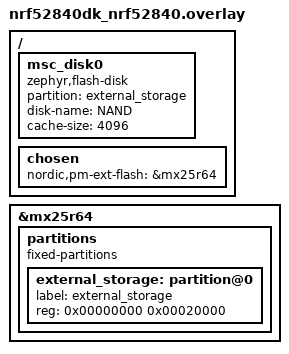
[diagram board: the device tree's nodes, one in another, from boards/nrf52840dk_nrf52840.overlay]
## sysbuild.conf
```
#
# Copyright (c) 2023 Nordic Semiconductor
#
# SPDX-License-Identifier: LicenseRef-Nordic-5-Clause
#

SB_CONFIG_BOOTLOADER_MCUBOOT=y
SB_CONFIG_DFU_ZIP=y
SB_CONFIG_DFU_ZIP_BLUETOOTH_MESH_METADATA=y
SB_CONFIG_DFU_ZIP_BLUETOOTH_MESH_FWID_CUSTOM=y
SB_CONFIG_DFU_ZIP_BLUETOOTH_MESH_FWID_CUSTOM_HEX="deadbeef"
```

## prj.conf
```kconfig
#
# Copyright (c) 2022 Nordic Semiconductor ASA
#
# SPDX-License-Identifier: LicenseRef-Nordic-5-Clause
#

# General configuration
CONFIG_SYSTEM_WORKQUEUE_STACK_SIZE=2048
CONFIG_NVS=y
CONFIG_SETTINGS=y
CONFIG_NVS_LOOKUP_CACHE=y
CONFIG_SETTINGS_NVS_NAME_CACHE=y
CONFIG_HWINFO=y
CONFIG_DK_LIBRARY=y
CONFIG_LOG=y
CONFIG_LTO=y
CONFIG_ISR_TABLES_LOCAL_DECLARATION=y

# Bootloader configuration
CONFIG_NCS_APPLICATION_BOOT_BANNER_STRING="Mesh DFU Distributor"
CONFIG_BOOTLOADER_MCUBOOT=y
CONFIG_NCS_SAMPLE_MCUMGR_BT_OTA_DFU=y
CONFIG_MCUBOOT_GENERATE_CONFIRMED_IMAGE=y
CONFIG_MCUBOOT_IMGTOOL_SIGN_VERSION="1.0.0+0"

# Bluetooth configuration
CONFIG_BT=y
CONFIG_BT_DEVICE_NAME="Mesh DFU Distributor"
CONFIG_BT_L2CAP_TX_BUF_COUNT=8
CONFIG_BT_OBSERVER=y
CONFIG_BT_PERIPHERAL=y
CONFIG_BT_SETTINGS=y
CONFIG_BT_ECC=y
CONFIG_BT_TINYCRYPT_ECC=y
CONFIG_BT_BUF_CMD_TX_COUNT=4

# Disable unused Bluetooth features
CONFIG_BT_CTLR_LE_ENC=n
CONFIG_BT_DATA_LEN_UPDATE=n
CONFIG_BT_PHY_UPDATE=n
CONFIG_BT_CTLR_CHAN_SEL_2=n
CONFIG_BT_CTLR_PRIVACY=n
CONFIG_BT_CTLR_PHY_2M=n

# Bluetooth Mesh configuration
CONFIG_BT_MESH=y
CONFIG_BT_MESH_RELAY=y
CONFIG_BT_MESH_FRIEND=y
CONFIG_BT_MESH_MSG_CACHE_SIZE=256
CONFIG_BT_MESH_ADV_BUF_COUNT=128
CONFIG_BT_MESH_TX_SEG_MAX=10
CONFIG_BT_MESH_RX_SEG_MAX=10
CONFIG_BT_MESH_TX_SEG_MSG_COUNT=2
CONFIG_BT_MESH_RX_SEG_MSG_COUNT=2
CONFIG_BT_MESH_PB_GATT=y
CONFIG_BT_MESH_PB_ADV=y
CONFIG_BT_MESH_GATT_PROXY=y
CONFIG_BT_MESH_SHELL=y
CONFIG_BT_MESH_DK_PROV=y
CONFIG_BT_MESH_PROXY_USE_DEVICE_NAME=y
CONFIG_BT_MESH_MODEL_EXTENSIONS=y

# Bluetooth Mesh models
CONFIG_BT_MESH_BLOB_SRV=y
CONFIG_BT_MESH_BLOB_IO_FLASH=y
CONFIG_BT_MESH_BLOB_CLI=y
CONFIG_BT_MESH_DFU_SRV=y
CONFIG_BT_MESH_DFU_METADATA=y
CONFIG_BT_MESH_DFU_CLI=y
CONFIG_BT_MESH_DFD_SRV=y
CONFIG_BT_MESH_SAR_CFG_SRV=y

# Reconfigure transport SAR for DFU
# Increase probability of delivering segmented messages
CONFIG_BT_MESH_SAR_TX_UNICAST_RETRANS_COUNT=0x5
CONFIG_BT_MESH_SAR_TX_UNICAST_RETRANS_WITHOUT_PROG_COUNT=0x3
# Reduce amount of generated SegAcks
CONFIG_BT_MESH_SAR_RX_ACK_RETRANS_COUNT=0x0
CONFIG_BT_MESH_SAR_RX_ACK_DELAY_INC=0x7
CONFIG_BT_MESH_SAR_RX_SEG_INT_STEP=0xf
CONFIG_BT_MESH_SAR_RX_SEG_THRESHOLD=0x1f

# Debug configuration
CONFIG_LOG_BACKEND_UART=y
CONFIG_BT_MESH_LOG_LEVEL_DBG=y
CONFIG_BT_MESH_MODEL_LOG_LEVEL_DBG=y
CONFIG_BT_MESH_DFU_LOG_LEVEL_DBG=y
CONFIG_BT_MESH_PROVISIONEE_LOG_LEVEL_INF=y

# Additional simultaneous connections for SMP BT.
CONFIG_BT_MAX_CONN=3
CONFIG_BT_CTLR_ADV_SET=6
CONFIG_BT_EXT_ADV_MAX_ADV_SET=6

# One extra identity for SMP service
CONFIG_BT_ID_MAX=2

# MCUmgr shell support
CONFIG_SHELL_BACKEND_SERIAL=n
CONFIG_SHELL_BACKEND_RTT=y
CONFIG_MCUMGR_GRP_SHELL=y
CONFIG_SHELL_BACKEND_DUMMY=y
CONFIG_SHELL_BACKEND_DUMMY_BUF_SIZE=1000
CONFIG_SEGGER_RTT_BUFFER_SIZE_DOWN=100

# MCUmgr UART transport
CONFIG_BASE64=y
CONFIG_MCUMGR_TRANSPORT_UART=y

# This option may not be enabled automatically for some boards. Enabling it explicitly to avoid
# missing configuration.
CONFIG_USE_SEGGER_RTT=y

CONFIG_BT_MESH_CDB=y
CONFIG_BT_MESH_PROVISIONER=y
CONFIG_BT_MESH_SHELL_PROV=y
CONFIG_BT_MESH_SHELL_PROV_CTX_INSTANCE=y
CONFIG_BT_MESH_RPR_CLI=y
CONFIG_BT_MESH_SHELL_RPR_CLI=y

CONFIG_BT_MESH_ONOFF_SRV=y
CONFIG_BT_MESH_RPR_SRV=y
CONFIG_BT_MESH_CFG_CLI=y

CONFIG_BT_MESH_PROVISIONER=y
CONFIG_BT_MESH_CDB=y
```

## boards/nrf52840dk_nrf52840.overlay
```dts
/*
 * Copyright (c) 2023 Nordic Semiconductor ASA
 *
 * SPDX-License-Identifier: Apache-2.0
 */

&mx25r64 {
	partitions {
		compatible = "fixed-partitions";
		#address-cells = <1>;
		#size-cells = <1>;

		external_storage: partition@0 {
			label = "external_storage";
			reg = <0x00000000 0x00020000>;
		};
	};
};

/ {
	msc_disk0 {
		compatible = "zephyr,flash-disk";
		partition = <&external_storage>;
		disk-name = "NAND";
		cache-size = <4096>;
	};
	chosen {
		nordic,pm-ext-flash = &mx25r64;
	};
};
```

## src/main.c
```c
/*
 * Copyright (c) 2022 Nordic Semiconductor ASA
 *
 * SPDX-License-Identifier: LicenseRef-Nordic-5-Clause
 */

/** @file
 *  @brief Bluetooth Mesh DFU Distributor role sample
 */
#include <zephyr/kernel.h>
#include <zephyr/sys/reboot.h>
#include <zephyr/storage/flash_map.h>
#include <zephyr/bluetooth/bluetooth.h>
#include <zephyr/bluetooth/mesh.h>
#include <zephyr/bluetooth/mesh/shell.h>
#include <bluetooth/mesh/vnd/le_pair_resp.h>
#include <bluetooth/mesh/dk_prov.h>
#include <bluetooth/mesh/models.h>
#include <dk_buttons_and_leds.h>
#include "smp_bt.h"
#include "dfu_dist.h"
#include "dfu_target.h"

#include <zephyr/dfu/mcuboot.h>

static struct bt_mesh_blob_io_flash blob_flash_stream;

/* Set up a repeating delayed work to blink the DK's LEDs when attention is
 * requested.
 */
static struct k_work_delayable attention_blink_work;
static bool attention;

static void attention_blink(struct k_work *work)
{
	static int idx;
	const uint8_t pattern[] = {
#if DT_NODE_EXISTS(DT_ALIAS(led0))
		BIT(0),
#endif
#if DT_NODE_EXISTS(DT_ALIAS(led1))
		BIT(1),
#endif
#if DT_NODE_EXISTS(DT_ALIAS(led2))
		BIT(2),
#endif
#if DT_NODE_EXISTS(DT_ALIAS(led3))
		BIT(3),
#endif
	};

	if (attention) {
		dk_set_leds(pattern[idx++ % ARRAY_SIZE(pattern)]);
		k_work_reschedule(&attention_blink_work, K_MSEC(30));
	} else {
		dk_set_leds(DK_NO_LEDS_MSK);
	}
}

static void attention_on(const struct bt_mesh_model *mod)
{
	attention = true;
	k_work_reschedule(&attention_blink_work, K_NO_WAIT);
}

static void attention_off(const struct bt_mesh_model *mod)
{
	/* Will stop rescheduling blink timer */
	attention = false;
}

static const struct bt_mesh_health_srv_cb health_srv_cb = {
	.attn_on = attention_on,
	.attn_off = attention_off,
};

static struct bt_mesh_health_srv health_srv = {
	.cb = &health_srv_cb,
};

BT_MESH_HEALTH_PUB_DEFINE(health_pub, 0);

static void led_set(struct bt_mesh_onoff_srv *srv, struct bt_mesh_msg_ctx *ctx,
		    const struct bt_mesh_onoff_set *set,
		    struct bt_mesh_onoff_status *rsp)
{
}

static void led_get(struct bt_mesh_onoff_srv *srv, struct bt_mesh_msg_ctx *ctx,
		    struct bt_mesh_onoff_status *rsp)
{
}

static const struct bt_mesh_onoff_srv_handlers onoff_handlers = {
	.set = led_set,
	.get = led_get,
};

static struct bt_mesh_onoff_srv onoff_srv = BT_MESH_ONOFF_SRV_INIT(onoff_srv, &onoff_handlers);

static struct bt_mesh_cfg_cli cfg_cli;

static struct bt_mesh_rpr_cli rpr_cli = BT_MESH_RPR_CLI_INIT(rpr_cli, NULL);

#if 1
static const struct bt_mesh_model * primary_models[] = {
	BT_MESH_MODEL_DECLARE(BT_MESH_MODEL_CFG_SRV),
	BT_MESH_MODEL_DECLARE(BT_MESH_MODEL_HEALTH_SRV(&health_srv, &health_pub)),
	BT_MESH_MODEL_DECLARE(BT_MESH_MODEL_CFG_CLI(&cfg_cli)),
	BT_MESH_MODEL_DECLARE(BT_MESH_MODEL_RPR_SRV),
	BT_MESH_MODEL_DFD_SRV(&dfd_srv),
	BT_MESH_MODEL_RPR_CLI(&rpr_cli),
	BT_MESH_MODEL_ONOFF_SRV(&onoff_srv),
};

static const struct bt_mesh_model * primary_vnd_models[] = {
#if CONFIG_BT_MESH_LE_PAIR_RESP
	BT_MESH_MODEL_DECLARE(BT_MESH_MODEL_LE_PAIR_RESP),
#endif
};

static const struct bt_mesh_model * secondary_models[] = {
	BT_MESH_MODEL_DFU_SRV(&dfu_srv),
};

static struct bt_mesh_elem elements[] = {
	BT_MESH_ELEM(1, primary_models,
		     primary_vnd_models),
	BT_MESH_ELEM(2, secondary_models,
		     BT_MESH_MODEL_PTR_LIST()),
};
#else
static struct bt_mesh_elem elements[] = {
	BT_MESH_ELEM(1, BT_MESH_MODEL_PTR_LIST(BT_MESH_MODEL_DECLARE(BT_MESH_MODEL_CFG_SRV),
					       BT_MESH_MODEL_DECLARE(BT_MESH_MODEL_HEALTH_SRV(&health_srv, &health_pub)),
					       BT_MESH_MODEL_DFD_SRV(&dfd_srv),
					       BT_MESH_MODEL_DECLARE(BT_MESH_MODEL_RPR_CLI(&bt_mesh_shell_rpr_cli))),
		     BT_MESH_MODEL_PTR_LIST(
#if CONFIG_BT_MESH_LE_PAIR_RESP
					    BT_MESH_MODEL_LE_PAIR_RESP,
#endif
					    )),
	BT_MESH_ELEM(2, BT_MESH_MODEL_PTR_LIST(BT_MESH_MODEL_DFU_SRV(&dfu_srv)),
		     BT_MESH_MODEL_PTR_LIST()),
};
#endif


static const struct bt_mesh_comp comp = {
	.cid = CONFIG_BT_COMPANY_ID,
	.elem = elements,
	.elem_count = ARRAY_SIZE(elements),
};

static void reboot_work_handler(struct k_work *work)
{
	sys_reboot(SYS_REBOOT_WARM);
}

static K_WORK_DELAYABLE_DEFINE(reboot_work, reboot_work_handler);

static void reprovisioned(uint16_t addr)
{
	printk("Reprovisioned by RPR client, address: 0x%04x. Rebooting...\n", addr);
	boot_request_upgrade(BOOT_UPGRADE_TEST);
	k_work_schedule(&reboot_work, K_SECONDS(3));
}

static void bt_ready(int err)
{
	if (err) {
		printk("Bluetooth init failed (err %d)\n", err);
		return;
	}

	printk("Bluetooth initialized\n");

	err = dk_leds_init();
	if (err) {
		printk("Initializing LEDs failed (err %d)\n", err);
		return;
	}

	bt_mesh_shell_prov.reprovisioned = reprovisioned;

	err = bt_mesh_init(&bt_mesh_shell_prov, &comp);
//	err = bt_mesh_init(bt_mesh_dk_prov_init(), &comp);
	if (err) {
		printk("Initializing mesh failed (err %d)\n", err);
		return;
	}

	if (IS_ENABLED(CONFIG_SETTINGS)) {
		settings_load();
	}

	bt_mesh_prov_enable(BT_MESH_PROV_ADV | BT_MESH_PROV_GATT);

	printk("Mesh initialized\n");

	/* Start advertising SMP BT service. */
	err = smp_dfu_init();
	if (err) {
		printk("SMP initialization failed (err: %d)\n", err);
	}

	/* Confirm the image and mark it as applied after the mesh started. */
	dfu_target_image_confirm();
}

int main(void)
{
	int err;

	printk("Initializing...\n");

	err = bt_mesh_blob_io_flash_init(&blob_flash_stream,
					 FIXED_PARTITION_ID(slot1_partition), 0);
	if (err) {
		printk("Failed to init BLOB IO Flash module: %d\n", err);
		return 1;
	}

	k_work_init_delayable(&attention_blink_work, attention_blink);
	dfu_distributor_init(&blob_flash_stream);
	dfu_target_init(&blob_flash_stream);

	err = bt_enable(bt_ready);
	if (err) {
		printk("Bluetooth init failed (err %d)\n", err);
		return 2;
	}
	return 0;
}
```

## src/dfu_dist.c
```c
/*
 * Copyright (c) 2022 Nordic Semiconductor ASA
 *
 * SPDX-License-Identifier: LicenseRef-Nordic-5-Clause
 */

#include "dfu_dist.h"

static struct bt_mesh_blob_io_flash *blob_flash_stream;

static void slot_info_print(const struct bt_mesh_dfu_slot *slot, const uint8_t *idx)
{
	char fwid[2 * CONFIG_BT_MESH_DFU_FWID_MAXLEN + 1];
	char metadata[2 * CONFIG_BT_MESH_DFU_METADATA_MAXLEN + 1];
	size_t len;

	len = bin2hex(slot->fwid, slot->fwid_len, fwid, sizeof(fwid));
	fwid[len] = '\0';
	len = bin2hex(slot->metadata, slot->metadata_len, metadata,
		      sizeof(metadata));
	metadata[len] = '\0';

	if (idx != NULL) {
		printk("Slot %u:\n", *idx);
	} else {
		printk("Slot:\n");
	}
	printk("\tSize:     %u bytes\n", slot->size);
	printk("\tFWID:     %s\n", fwid);
	printk("\tMetadata: %s\n", metadata);
}

static int dfd_srv_recv(struct bt_mesh_dfd_srv *srv,
			const struct bt_mesh_dfu_slot *slot,
			const struct bt_mesh_blob_io **io)
{
	printk("Uploading new firmware image to the distributor.\n");
	slot_info_print(slot, NULL);

	*io = &blob_flash_stream->io;

	return 0;
}

static void dfd_srv_del(struct bt_mesh_dfd_srv *srv,
			const struct bt_mesh_dfu_slot *slot)
{
	printk("Deleting the firmware image from the distributor.\n");
	slot_info_print(slot, NULL);
}

static int dfd_srv_send(struct bt_mesh_dfd_srv *srv,
			const struct bt_mesh_dfu_slot *slot,
			const struct bt_mesh_blob_io **io)
{
	printk("Starting the firmware distribution.\n");
	slot_info_print(slot, NULL);

	*io = &blob_flash_stream->io;

	return 0;
}

static const char *dfd_phase_to_str(enum bt_mesh_dfd_phase phase)
{
	switch (phase) {
	case BT_MESH_DFD_PHASE_IDLE:
		return "Idle";
	case BT_MESH_DFD_PHASE_TRANSFER_ACTIVE:
		return "Transfer Active";
	case BT_MESH_DFD_PHASE_TRANSFER_SUCCESS:
		return "Transfer Success";
	case BT_MESH_DFD_PHASE_APPLYING_UPDATE:
		return "Applying Update";
	case BT_MESH_DFD_PHASE_COMPLETED:
		return "Completed";
	case BT_MESH_DFD_PHASE_FAILED:
		return "Failed";
	case BT_MESH_DFD_PHASE_CANCELING_UPDATE:
		return "Canceling Update";
	case BT_MESH_DFD_PHASE_TRANSFER_SUSPENDED:
		return "Transfer Suspended";
	default:
		return "Unknown Phase";
	}
}

static void dfd_srv_phase(struct bt_mesh_dfd_srv *srv, enum bt_mesh_dfd_phase phase)
{
	printk("Distribution phase changed to %s\n", dfd_phase_to_str(phase));
}

static struct bt_mesh_dfd_srv_cb dfd_srv_cb = {
	.recv = dfd_srv_recv,
	.del = dfd_srv_del,
	.send = dfd_srv_send,
	.phase = dfd_srv_phase,
};

struct bt_mesh_dfd_srv dfd_srv = BT_MESH_DFD_SRV_INIT(dfd_srv, &dfd_srv_cb);

void dfu_distributor_init(struct bt_mesh_blob_io_flash *flash_stream)
{
	blob_flash_stream = flash_stream;
}
```

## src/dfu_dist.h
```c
/*
 * Copyright (c) 2022 Nordic Semiconductor ASA
 *
 * SPDX-License-Identifier: LicenseRef-Nordic-5-Clause
 */

#ifndef DFU_DIST_H__
#define DFU_DIST_H__

#include <zephyr/bluetooth/mesh.h>

#ifdef __cplusplus
extern "C" {
#endif

extern struct bt_mesh_dfd_srv dfd_srv;

void dfu_distributor_init(struct bt_mesh_blob_io *flash_stream);

#ifdef __cplusplus
}
#endif

#endif /* DFU_DIST_H__ */
```

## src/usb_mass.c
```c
/*
 * Copyright (c) 2016 Intel Corporation.
 * Copyright (c) 2019-2020 Nordic Semiconductor ASA
 *
 * SPDX-License-Identifier: Apache-2.0
 */

#include <zephyr/kernel.h>
#include <zephyr/logging/log.h>
#include <zephyr/usb/usb_device.h>
#include <zephyr/usb/usbd.h>
#include <zephyr/usb/class/usbd_msc.h>
#include <zephyr/fs/fs.h>
#include <stdio.h>

#include <zephyr/bluetooth/mesh.h>

LOG_MODULE_REGISTER(main);

#include <zephyr/storage/flash_map.h>
#include <ff.h>

#define STORAGE_PARTITION		external_storage
#define STORAGE_PARTITION_ID		FIXED_PARTITION_ID(STORAGE_PARTITION)

static struct fs_mount_t fs_mnt;

static int setup_flash(struct fs_mount_t *mnt)
{
	int rc = 0;
	unsigned int id;
	const struct flash_area *pfa;

	mnt->storage_dev = (void *)STORAGE_PARTITION_ID;
	id = STORAGE_PARTITION_ID;

	rc = flash_area_open(id, &pfa);
	printk("Area %u at 0x%x on %s for %u bytes\n",
	       id, (unsigned int)pfa->fa_off, pfa->fa_dev->name,
	       (unsigned int)pfa->fa_size);

	if (rc < 0 /*&& IS_ENABLED(CONFIG_APP_WIPE_STORAGE) */) {
		printk("Erasing flash area ... ");
		rc = flash_area_erase(pfa, 0, pfa->fa_size);
		printk("%d\n", rc);
	}

	if (rc < 0) {
		flash_area_close(pfa);
	}

	return rc;
}

static int mount_app_fs(struct fs_mount_t *mnt)
{
	int rc;

	static FATFS fat_fs;

	mnt->type = FS_FATFS;
	mnt->fs_data = &fat_fs;
	mnt->mnt_point = "/NAND:";

	rc = fs_mount(mnt);

	return rc;
}

static void setup_disk(void)
{
	struct fs_mount_t *mp = &fs_mnt;
	struct fs_dir_t dir;
	struct fs_statvfs sbuf;
	int rc;

	fs_dir_t_init(&dir);

	rc = setup_flash(mp);
	if (rc < 0) {
		LOG_ERR("Failed to setup flash area");
		return;
	}

	rc = mount_app_fs(mp);
	if (rc < 0) {
		LOG_ERR("Failed to mount filesystem");
		return;
	}

	/* Allow log messages to flush to avoid interleaved output */
	k_sleep(K_MSEC(50));

	printk("Mount %s: %d\n", fs_mnt.mnt_point, rc);

	rc = fs_statvfs(mp->mnt_point, &sbuf);
	if (rc < 0) {
		printk("FAIL: statvfs: %d\n", rc);
		return;
	}

	printk("%s: bsize = %lu ; frsize = %lu ;"
	       " blocks = %lu ; bfree = %lu\n",
	       mp->mnt_point,
	       sbuf.f_bsize, sbuf.f_frsize,
	       sbuf.f_blocks, sbuf.f_bfree);

	rc = fs_opendir(&dir, mp->mnt_point);
	printk("%s opendir: %d\n", mp->mnt_point, rc);

	if (rc < 0) {
		LOG_ERR("Failed to open directory");
	}

	while (rc >= 0) {
		struct fs_dirent ent = { 0 };

		rc = fs_readdir(&dir, &ent);
		if (rc < 0) {
			LOG_ERR("Failed to read directory entries");
			break;
		}
		if (ent.name[0] == 0) {
			printk("End of files\n");
			break;
		}
		printk("  %c %u %s\n",
		       (ent.type == FS_DIR_ENTRY_FILE) ? 'F' : 'D',
		       ent.size,
		       ent.name);
	}

	(void)fs_closedir(&dir);

	return;
}

static struct fs_file_t image_file;

static int blob_io_open(const struct bt_mesh_blob_io *io,
		    const struct bt_mesh_blob_xfer *xfer,
		    enum bt_mesh_blob_io_mode mode)
{
	char fname[100];
	int err;

	snprintf(fname, sizeof(fname), "%s/APP_UP~1.BIN", fs_mnt.mnt_point);

	err = fs_open(&image_file, fname, FS_O_READ);
	if (err) {
		printk("Unable to open file: %d\n", err);
		return -1;
	}

	return 0;
}

static void blob_io_close(const struct bt_mesh_blob_io *io,
		      const struct bt_mesh_blob_xfer *xfer)
{
	int err;

	err = fs_close(&image_file);
	if (err) {
		printk("Unable to close file: %d\n", err);
	}
}

static int blob_io_block_start(const struct bt_mesh_blob_io *io,
			   const struct bt_mesh_blob_xfer *xfer,
			   const struct bt_mesh_blob_block *block)
{
	return 0;
}

static void blob_io_block_end(const struct bt_mesh_blob_io *io,
			  const struct bt_mesh_blob_xfer *xfer,
			  const struct bt_mesh_blob_block *block)
{
}

static int blob_io_wr(const struct bt_mesh_blob_io *io,
		  const struct bt_mesh_blob_xfer *xfer,
		  const struct bt_mesh_blob_block *block,
		  const struct bt_mesh_blob_chunk *chunk)
{
	return 0;
}

static int blob_io_rd(const struct bt_mesh_blob_io *io,
		  const struct bt_mesh_blob_xfer *xfer,
		  const struct bt_mesh_blob_block *block,
		  const struct bt_mesh_blob_chunk *chunk)
{
	int err;

	err = fs_seek(&image_file, block->offset + chunk->offset, FS_SEEK_SET);
	if (err) {
		printk("Failed to set new file position: %d\n", err);
		return -1;
	}

	err = fs_read(&image_file, chunk->data, chunk->size);
	if (err < 0) {
		printk("Failed to read from file: %d\n", err);
	}

	return 0;
}

static struct bt_mesh_blob_io usb_mass_blob_io = {
	.open = blob_io_open,
	.close = blob_io_close,
	.block_start = blob_io_block_start,
	.block_end = blob_io_block_end,
	.wr = blob_io_wr,
	.rd = blob_io_rd,
};

int usb_flash_stream_init(struct bt_mesh_blob_io **blob_io)
{
	int ret;

	setup_disk();

	ret = usb_enable(NULL);
	if (ret != 0) {
		LOG_ERR("Failed to enable USB");
		return 0;
	}

	LOG_INF("The device is put in USB mass storage mode.\n");

	*blob_io = &usb_mass_blob_io;
	fs_file_t_init(&image_file);
	return 0;
}
```

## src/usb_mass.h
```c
int usb_flash_stream_init(struct bt_mesh_blob_io **blob_io);
```
